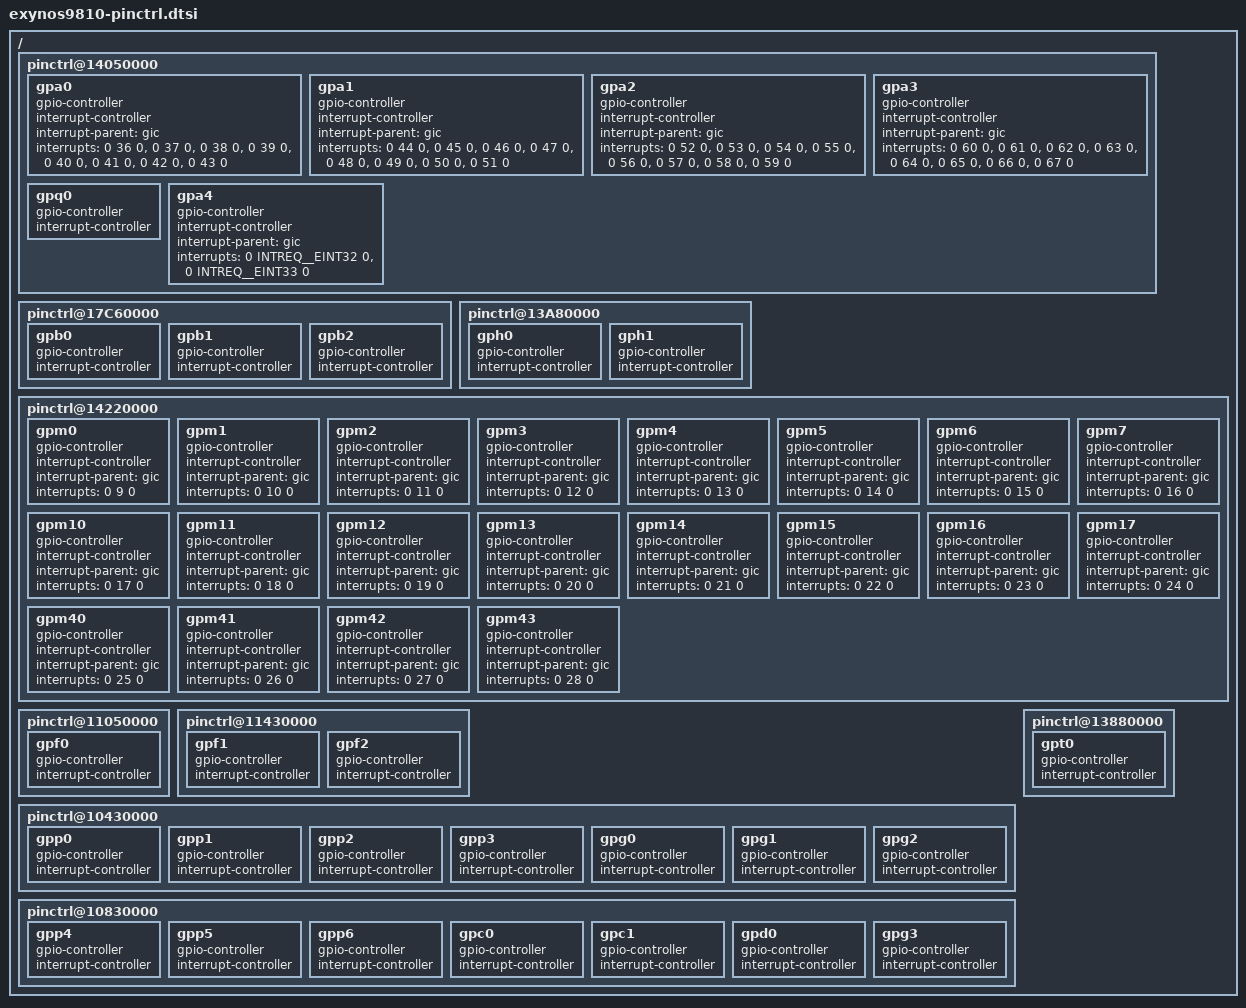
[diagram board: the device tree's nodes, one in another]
/*
 * Samsung's Exynos9810 SoC pin-mux and pin-config device tree source
 *
 * Copyright (c) 2017 Samsung Electronics Co., Ltd.
 *		http://www.samsung.com
 *
 * Samsung's Exynos9810 SoC pin-mux and pin-config options are listed as device
 * tree nodes are listed in this file.
 *
 * This program is free software; you can redistribute it and/or modify
 * it under the terms of the GNU General Public License version 2 as
 * published by the Free Software Foundation.
*/

/ {
	/* ALIVE */
	pinctrl@14050000 {
		gpa0: gpa0 {
			gpio-controller;
			#gpio-cells = <2>;

			interrupt-controller;
			#interrupt-cells = <3>;
			interrupt-parent = <&gic>;
			interrupts = <0 36 0>, <0 37 0>, <0 38 0>, <0 39 0>,
				     <0 40 0>, <0 41 0>, <0 42 0>, <0 43 0>;
		};

		gpa1: gpa1 {
			gpio-controller;
			#gpio-cells = <2>;

			interrupt-controller;
			#interrupt-cells = <3>;
			interrupt-parent = <&gic>;
			interrupts = <0 44 0>, <0 45 0>, <0 46 0>, <0 47 0>,
				     <0 48 0>, <0 49 0>, <0 50 0>, <0 51 0>;
		};

		gpa2: gpa2 {
			gpio-controller;
			#gpio-cells = <2>;

			interrupt-controller;
			#interrupt-cells = <3>;
			interrupt-parent = <&gic>;
			interrupts = <0 52 0>, <0 53 0>, <0 54 0>, <0 55 0>,
				     <0 56 0>, <0 57 0>, <0 58 0>, <0 59 0>;
		};

		gpa3: gpa3 {
			gpio-controller;
			#gpio-cells = <2>;

			interrupt-controller;
			#interrupt-cells = <3>;
			interrupt-parent = <&gic>;
			interrupts = <0 60 0>, <0 61 0>, <0 62 0>, <0 63 0>,
				     <0 64 0>, <0 65 0>, <0 66 0>, <0 67 0>;
		};

		gpq0: gpq0 {
			gpio-controller;
			#gpio-cells = <2>;

			interrupt-controller;
			#interrupt-cells = <2>;
		};

		gpa4: gpa4 {
			gpio-controller;
			#gpio-cells = <2>;

			interrupt-controller;
			#interrupt-cells = <3>;
			interrupt-parent = <&gic>;
			interrupts = <0 INTREQ__EINT32 0>, <0 INTREQ__EINT33 0>;
		};
	};

	/* AUD */
	pinctrl@17C60000 {
		gpb0: gpb0 {
			gpio-controller;
			#gpio-cells = <2>;

			interrupt-controller;
			#interrupt-cells = <2>;
		};

		gpb1: gpb1 {
			gpio-controller;
			#gpio-cells = <2>;

			interrupt-controller;
			#interrupt-cells = <2>;
		};

		gpb2: gpb2 {
			gpio-controller;
			#gpio-cells = <2>;

			interrupt-controller;
			#interrupt-cells = <2>;
		};
	};

	/* CHUB */
	pinctrl@13A80000 {
		gph0: gph0 {
			gpio-controller;
			#gpio-cells = <2>;

			interrupt-controller;
			#interrupt-cells = <2>;
		};

		gph1: gph1 {
			gpio-controller;
			#gpio-cells = <2>;

			interrupt-controller;
			#interrupt-cells = <2>;
		};
	};

	/* CMGP */
	pinctrl@14220000 {
		gpm0: gpm0 {
			gpio-controller;
			#gpio-cells = <2>;

			interrupt-controller;
			#interrupt-cells = <3>;
			interrupt-parent = <&gic>;
			interrupts = <0 9 0>;
		};

		gpm1: gpm1 {
			gpio-controller;
			#gpio-cells = <2>;

			interrupt-controller;
			#interrupt-cells = <3>;
			interrupt-parent = <&gic>;
			interrupts = <0 10 0>;
		};

		gpm2: gpm2 {
			gpio-controller;
			#gpio-cells = <2>;

			interrupt-controller;
			#interrupt-cells = <3>;
			interrupt-parent = <&gic>;
			interrupts = <0 11 0>;
		};

		gpm3: gpm3 {
			gpio-controller;
			#gpio-cells = <2>;

			interrupt-controller;
			#interrupt-cells = <3>;
			interrupt-parent = <&gic>;
			interrupts = <0 12 0>;
		};

		gpm4: gpm4 {
			gpio-controller;
			#gpio-cells = <2>;

			interrupt-controller;
			#interrupt-cells = <3>;
			interrupt-parent = <&gic>;
			interrupts = <0 13 0>;
		};

		gpm5: gpm5 {
			gpio-controller;
			#gpio-cells = <2>;

			interrupt-controller;
			#interrupt-cells = <3>;
			interrupt-parent = <&gic>;
			interrupts = <0 14 0>;
		};

		gpm6: gpm6 {
			gpio-controller;
			#gpio-cells = <2>;

			interrupt-controller;
			#interrupt-cells = <3>;
			interrupt-parent = <&gic>;
			interrupts = <0 15 0>;
		};

		gpm7: gpm7 {
			gpio-controller;
			#gpio-cells = <2>;

			interrupt-controller;
			#interrupt-cells = <3>;
			interrupt-parent = <&gic>;
			interrupts = <0 16 0>;
		};

		gpm10: gpm10 {
			gpio-controller;
			#gpio-cells = <2>;

			interrupt-controller;
			#interrupt-cells = <3>;
			interrupt-parent = <&gic>;
			interrupts = <0 17 0>;
		};

		gpm11: gpm11 {
			gpio-controller;
			#gpio-cells = <2>;


			interrupt-controller;
			#interrupt-cells = <3>;
			interrupt-parent = <&gic>;
			interrupts = <0 18 0>;
		};

		gpm12: gpm12 {
			gpio-controller;
			#gpio-cells = <2>;

			interrupt-controller;
			#interrupt-cells = <3>;
			interrupt-parent = <&gic>;
			interrupts = <0 19 0>;
		};

		gpm13: gpm13 {
			gpio-controller;
			#gpio-cells = <2>;

			interrupt-controller;
			#interrupt-cells = <3>;
			interrupt-parent = <&gic>;
			interrupts = <0 20 0>;
		};

		gpm14: gpm14 {
			gpio-controller;
			#gpio-cells = <2>;

			interrupt-controller;
			#interrupt-cells = <3>;
			interrupt-parent = <&gic>;
			interrupts = <0 21 0>;
		};

		gpm15: gpm15 {
			gpio-controller;
			#gpio-cells = <2>;

			interrupt-controller;
			#interrupt-cells = <3>;
			interrupt-parent = <&gic>;
			interrupts = <0 22 0>;
		};

		gpm16: gpm16 {
			gpio-controller;
			#gpio-cells = <2>;

			interrupt-controller;
			#interrupt-cells = <3>;
			interrupt-parent = <&gic>;
			interrupts = <0 23 0>;
		};

		gpm17: gpm17 {
			gpio-controller;
			#gpio-cells = <2>;

			interrupt-controller;
			#interrupt-cells = <3>;
			interrupt-parent = <&gic>;
			interrupts = <0 24 0>;
		};

		gpm40: gpm40 {
			gpio-controller;
			#gpio-cells = <2>;


			interrupt-controller;
			#interrupt-cells = <3>;
			interrupt-parent = <&gic>;
			interrupts = <0 25 0>;
		};

		gpm41: gpm41 {
			gpio-controller;
			#gpio-cells = <2>;

			interrupt-controller;
			#interrupt-cells = <3>;
			interrupt-parent = <&gic>;
			interrupts = <0 26 0>;
		};

		gpm42: gpm42 {
			gpio-controller;
			#gpio-cells = <2>;

			interrupt-controller;
			#interrupt-cells = <3>;
			interrupt-parent = <&gic>;
			interrupts = <0 27 0>;
		};

		gpm43: gpm43 {
			gpio-controller;
			#gpio-cells = <2>;

			interrupt-controller;
			#interrupt-cells = <3>;
			interrupt-parent = <&gic>;
			interrupts = <0 28 0>;
		};
	};

	/* FSYS0 */
	pinctrl@11050000 {
		gpf0: gpf0 {
			gpio-controller;
			#gpio-cells = <2>;

			interrupt-controller;
			#interrupt-cells = <2>;
		};
	};

	/* FSYS1 */
	pinctrl@11430000 {
		gpf1: gpf1 {
			gpio-controller;
			#gpio-cells = <2>;

			interrupt-controller;
			#interrupt-cells = <2>;
		};
		gpf2: gpf2 {
			gpio-controller;
			#gpio-cells = <2>;

			interrupt-controller;
			#interrupt-cells = <2>;
		};
	};

	/* PERIC0 */
	pinctrl@10430000 {
		gpp0: gpp0 {
			gpio-controller;
			#gpio-cells = <2>;

			interrupt-controller;
			#interrupt-cells = <2>;
		};

		gpp1: gpp1 {
			gpio-controller;
			#gpio-cells = <2>;

			interrupt-controller;
			#interrupt-cells = <2>;
		};

		gpp2: gpp2 {
			gpio-controller;
			#gpio-cells = <2>;

			interrupt-controller;
			#interrupt-cells = <2>;
		};

		gpp3: gpp3 {
			gpio-controller;
			#gpio-cells = <2>;

			interrupt-controller;
			#interrupt-cells = <2>;
		};

		gpg0: gpg0 {
			gpio-controller;
			#gpio-cells = <2>;

			interrupt-controller;
			#interrupt-cells = <2>;
		};

		gpg1: gpg1 {
			gpio-controller;
			#gpio-cells = <2>;

			interrupt-controller;
			#interrupt-cells = <2>;
		};

		gpg2: gpg2 {
			gpio-controller;
			#gpio-cells = <2>;

			interrupt-controller;
			#interrupt-cells = <2>;
		};
	};

	/* PERIC1 */
	pinctrl@10830000 {
		gpp4: gpp4 {
			gpio-controller;
			#gpio-cells = <2>;

			interrupt-controller;
			#interrupt-cells = <2>;
		};

		gpp5: gpp5 {
			gpio-controller;
			#gpio-cells = <2>;

			interrupt-controller;
			#interrupt-cells = <2>;
		};

		gpp6: gpp6 {
			gpio-controller;
			#gpio-cells = <2>;

			interrupt-controller;
			#interrupt-cells = <2>;
		};

		gpc0: gpc0 {
			gpio-controller;
			#gpio-cells = <2>;

			interrupt-controller;
			#interrupt-cells = <2>;
		};

		gpc1: gpc1 {
			gpio-controller;
			#gpio-cells = <2>;

			interrupt-controller;
			#interrupt-cells = <2>;
		};

		gpd0: gpd0 {
			gpio-controller;
			#gpio-cells = <2>;

			interrupt-controller;
			#interrupt-cells = <2>;
		};

		gpg3: gpg3 {
			gpio-controller;
			#gpio-cells = <2>;

			interrupt-controller;
			#interrupt-cells = <2>;
		};
	};

	/* VTS */
	pinctrl@13880000 {
		gpt0: gpt0 {
			gpio-controller;
			#gpio-cells = <2>;

			interrupt-controller;
			#interrupt-cells = <2>;
		};
	};
};
